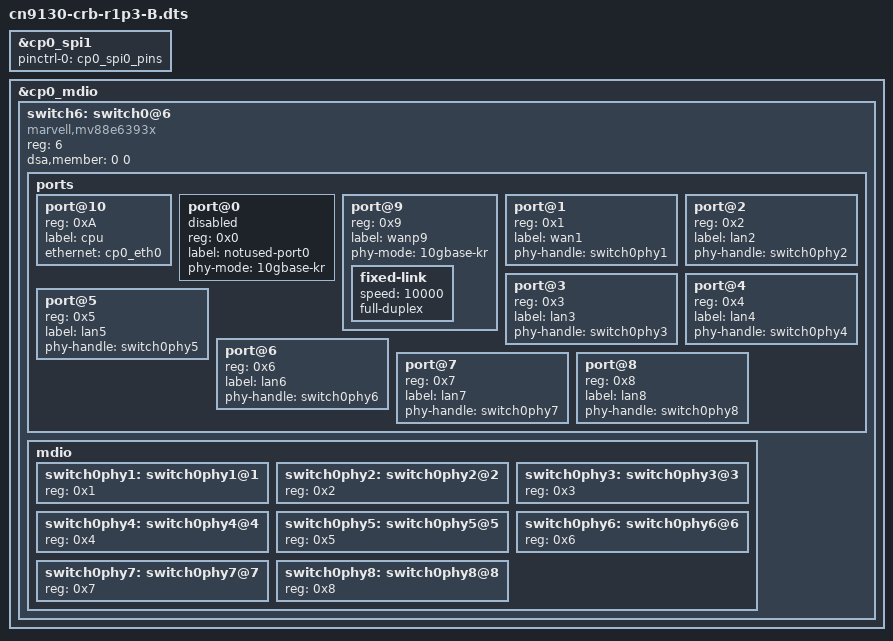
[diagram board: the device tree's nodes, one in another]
// SPDX-License-Identifier: GPL-2.0+
/*
 * Copyright (C) 2020 Marvell
 */

#include "cn9130-crb-B.dts"

&cp0_spi1 {
	pinctrl-0 = <&cp0_spi0_pins>;
};

&cp0_mdio {
	switch6: switch0@6 {
		compatible = "marvell,mv88e6393x";
		#address-cells = <1>;
		#size-cells = <0>;
		reg = <6>;
		dsa,member = <0 0>;
		ports {
			#address-cells = <1>;
			#size-cells = <0>;
			port@10 {
				reg = <0xA>;
				label = "cpu";
				ethernet = <&cp0_eth0>;
			};
			port@0 {
				reg = <0x0>;
				label = "notused-port0";
				phy-mode = "10gbase-kr";
				status = "disabled";
			};
			port@9 {
				reg = <0x9>;
				label = "wanp9";
				phy-mode = "10gbase-kr";
				fixed-link {
					speed = <10000>;
					full-duplex;
				};
			};
		       port@1 {
				reg = <0x1>;
				label = "wan1";
				phy-handle = <&switch0phy1>;
			};
			port@2 {
				reg = <0x2>;
				label = "lan2";
				phy-handle = <&switch0phy2>;
			};
			port@3 {
				reg = <0x3>;
				label = "lan3";
				phy-handle = <&switch0phy3>;
			};
			port@4 {
				reg = <0x4>;
				label = "lan4";
				phy-handle = <&switch0phy4>;
			};
			port@5 {
				reg = <0x5>;
				label = "lan5";
				phy-handle = <&switch0phy5>;
			};
			port@6 {
				reg = <0x6>;
				label = "lan6";
				phy-handle = <&switch0phy6>;
			};
			port@7 {
				reg = <0x7>;
				label = "lan7";
				phy-handle = <&switch0phy7>;
			};
			port@8 {
				reg = <0x8>;
				label = "lan8";
				phy-handle = <&switch0phy8>;
			};                };
		mdio {
			#address-cells = <1>;
			#size-cells = <0>;
			switch0phy1: switch0phy1@1 {
				reg = <0x1>;
			};
			switch0phy2: switch0phy2@2 {
				reg = <0x2>;
			};
			switch0phy3: switch0phy3@3 {
				reg = <0x3>;
			};
			switch0phy4: switch0phy4@4 {
				reg = <0x4>;
			};
			switch0phy5: switch0phy5@5 {
				reg = <0x5>;
			};
			switch0phy6: switch0phy6@6 {
				reg = <0x6>;
			};
			switch0phy7: switch0phy7@7 {
				reg = <0x7>;
			};
			switch0phy8: switch0phy8@8 {
				reg = <0x8>;
			};
		};
	};
};
